# forge_test register map
Vendor: forge-test; File version: 1.0
Forge MMIO test fixture
Registers are 32-bit, read-write, reset 0x0 unless marked. A register's access mark holds for its fields unless they carry their own. Offsets are from the block's base; lines under a group give offsets from that group; [hi:lo] are bit positions; {n}, {i} and the like mark numbered series; 'fields as' and 'values as' point back to an identical list; <NAME> marks a mode.

## Memory map
0x10000000 TESTPERIPH size 0x80 — Test peripheral for forge native MMIO tests.
0x10001000 PORT1 size 0x10 — Test port 1 (canonical) — drives the family-template path.
0x10001100 PORT2 size 0x10
0x10001200 PORT3 size 0x10

## TESTPERIPH — Test peripheral for forge native MMIO tests.
Base 0x10000000
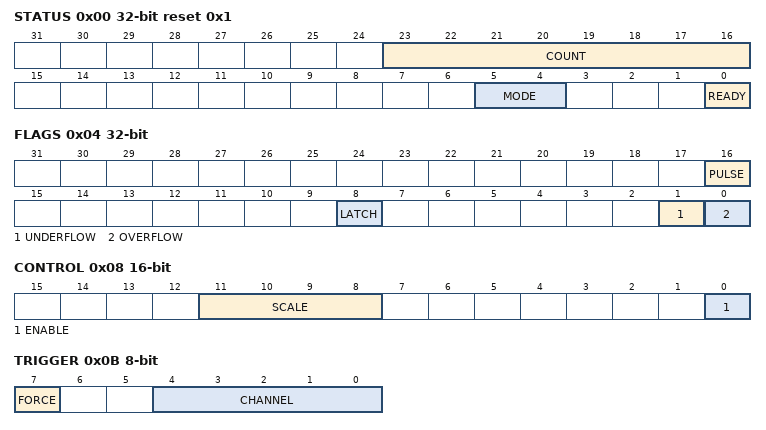
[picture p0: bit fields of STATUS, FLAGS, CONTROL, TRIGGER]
0x00 STATUS reset 0x1 — Status register: normal fields, enum, reserved gap.
  [23:16] COUNT — Counter
  [5:4] MODE — Operating mode
    0=IDLE; 1=ACTIVE; 2=SLEEP
  [0] READY — Device ready
0x04 FLAGS — Mixed flag register exercising W1C / W1S / W1T modify-write semantics.
  [16] PULSE write-1-toggles — W1T: write 1 to toggle.
  [8] LATCH write-1-sets — W1S: write 1 to set.
  [1] UNDERFLOW write-1-clears — W1C: write 1 to clear.
  [0] OVERFLOW write-1-clears — W1C: write 1 to clear.
0x08 CONTROL 16-bit — 16-bit control register.
  [11:8] SCALE — Scale value
  [0] ENABLE — Enable bit
0x0B TRIGGER 8-bit — 8-bit trigger register at an unaligned byte offset.
  [7] FORCE — Force-all flag
  [4:0] CHANNEL — Channel to trigger
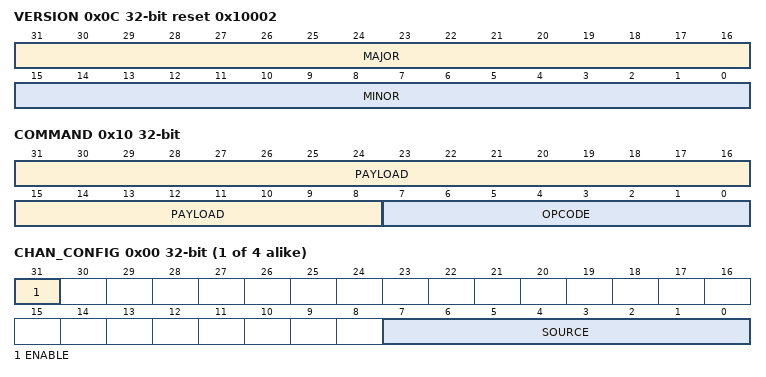
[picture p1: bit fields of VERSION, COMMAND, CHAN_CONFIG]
0x0C VERSION ro reset 0x10002 — Version ID (read-only).
  [31:16] MAJOR — Major version
  [15:0] MINOR — Minor version
0x10 COMMAND wo — Command register (write-only).
  [31:8] PAYLOAD — Payload word
  [7:0] OPCODE — Operation code
{0x20+4i} SLOT[{i}] (i=0..3) — Register array (single register replicated by dim).
  [31:0] VALUE
{0x40+0x10*i} CHAN[{i}] (i=0..3) group — Per-channel registers, exercises register clusters.
  0x00 CHAN_CONFIG — Channel config (32-bit). Inner addressOffset is cluster-relative.
    [31] ENABLE, [7:0] SOURCE
  0x08 CHAN_STATE 8-bit — Channel state (8-bit, exercises byte access in cluster).
    [7:0] VALUE
  {0xC+4j} CHAN_SETPOINT{j} (j=0..1) — Per-channel register array (nested array inside cluster).
    [31:0] POINT

## PORT1 — Test port 1 (canonical) — drives the family-template path.
Base 0x10001000
Same registers: PORT2 0x10001100, PORT3 0x10001200
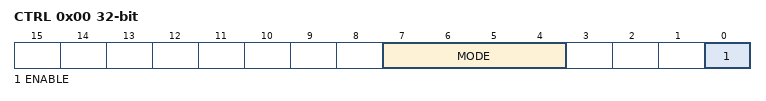
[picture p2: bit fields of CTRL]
0x00 CTRL — Control
  [7:4] MODE, [0] ENABLE
0x04 DATA
  [31:0] VALUE
